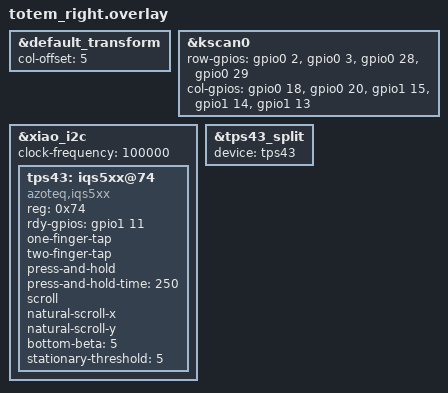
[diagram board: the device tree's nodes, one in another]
/*
 * Copyright (c) 2023 The ZMK Contributors
 *
 * SPDX-License-Identifier: MIT
 */

#include "totem.dtsi"

&default_transform {
    col-offset = <5>;
};

&kscan0 {
    row-gpios
        = <&gpio0 2 (GPIO_ACTIVE_HIGH | GPIO_PULL_DOWN)>
        , <&gpio0 3 (GPIO_ACTIVE_HIGH | GPIO_PULL_DOWN)>
        , <&gpio0 28 (GPIO_ACTIVE_HIGH | GPIO_PULL_DOWN)>
        , <&gpio0 29 (GPIO_ACTIVE_HIGH | GPIO_PULL_DOWN)>
        ;

    col-gpios
        = <&gpio0 18 GPIO_ACTIVE_HIGH>
        , <&gpio0 20 GPIO_ACTIVE_HIGH>
        , <&gpio1 15 GPIO_ACTIVE_HIGH>
        , <&gpio1 14 GPIO_ACTIVE_HIGH>
        , <&gpio1 13 GPIO_ACTIVE_HIGH>
        ;
};

&xiao_i2c {
    status = "okay";
    clock-frequency = <100000>;

    tps43: iqs5xx@74 {
        compatible = "azoteq,iqs5xx";
        reg = <0x74>;
        status = "okay";

        rdy-gpios = <&gpio1 11 GPIO_ACTIVE_HIGH>;

        one-finger-tap;
        two-finger-tap;
        press-and-hold;
        press-and-hold-time = <250>;
        scroll;
        natural-scroll-x;
        natural-scroll-y;
        bottom-beta = <5>;
        stationary-threshold = <5>;
    };
};

&tps43_split {
    device = <&tps43>;
};
